# F28x7x_cpu_timer_regs register map
Vendor: Texas Instruments
Peripheral module from a debugger description file (folder C2000).
Address unit: 16 bits
Registers are 16-bit, read-write, no defined reset value unless marked. A register's access mark holds for its fields unless they carry their own. Offsets are as the file gives them; lines under a group give offsets from that group; [hi:lo] are bit positions; {n}, {i} and the like mark numbered series; 'fields as' and 'values as' point back to an identical list; <NAME> marks a mode.

## CPU_TIMER_REGS
0x00 TIM — CPU-Timer, Counter Register
  [15:0] TIM — CPU-Timer Counter Registers
0x01 TIMH — CPU-Timer, Counter Register High
  [15:0] TIMH — CPU-Timer Counter Registers High
0x02 PRD — CPU-Timer, Period Register
  [15:0] PRD — CPU-Timer Period Registers
0x03 PRDH — CPU-Timer, Period Register High
  [15:0] PRDH — CPU-Timer Period Registers High
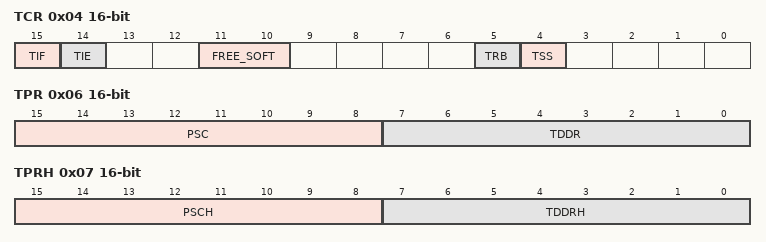
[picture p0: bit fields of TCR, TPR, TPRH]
0x04 TCR — CPU-Timer, Control Register
  [15] TIF — CPU-Timer Interrupt Flag.
    0=The CPU-Timer has not decremented to zero; 1=This flag gets set when the CPU-timer decrements to zero
  [14] TIE — CPU-Timer Interrupt Enable.
    0=The CPU-Timer interrupt is disabled; 1=The CPU-Timer interrupt is enabled
  [11:10] FREE_SOFT — Emulation modes
    0=Stop after the next decrement of the TIMH:TIM (hard stop); 1=Stop after the TIMH:TIM decrements to 0 (soft stop)[[br]][[br]]; 2=__2 (Free run); 3=__3 (Free run)
  [5] TRB — Timer reload
    0=The TRB bit is always read as zero. Writes of 0 are ignored.; 1=When you write a 1 to TRB, the TIMH:TIM is loaded with the valu
  [4] TSS — CPU-Timer stop status bit.
    0=Reads of 0 indicate the CPU-timer is running; 1=Reads of 1 indicate that the CPU-timer is stopped
0x06 TPR — CPU-Timer, Prescale Register
  [15:8] PSC — CPU-Timer Prescale Counter.
  [7:0] TDDR — CPU-Timer Divide-Down.
0x07 TPRH — CPU-Timer, Prescale Register High
  [15:8] PSCH — CPU-Timer Prescale Counter.
  [7:0] TDDRH — CPU-Timer Divide-Down.
